# GD32C231 register map
File version: 1.0
CPU: CM23 r0p0, little endian, MPU, FPU, 4 interrupt priority bits
Registers are 32-bit, read-write, reset 0x0 unless marked. A register's access mark holds for its fields unless they carry their own. Offsets are from the block's base; [hi:lo] are bit positions; {n}, {i} and the like mark numbered series; 'fields as' and 'values as' point back to an identical list.

## CRC — Cyclic redundancy checks management unit
Base 0x40023000
0x00 DATA reset 0xFFFFFFFF
  [31:0] DATA — CRC calculation result bits
0x04 FDATA — Free data register
  [7:0] FDATA — Free data register bits
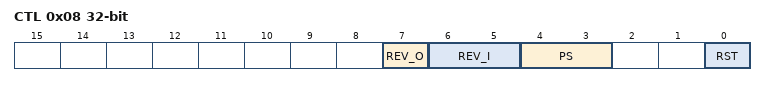
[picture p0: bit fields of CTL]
0x08 CTL — Control register
  [7] REV_O — Reverse output data value in bit order
  [6:5] REV_I — Reverse type for input data
  [4:3] PS — Size of polynomial
  [0] RST — Software writes and reads.
0x10 IDATA reset 0xFFFFFFFF — Initialization data register
  [31:0] IDATA — Configurable initial CRC data value
0x14 POLY reset 0x4C11DB7 — Polynomial register
  [31:0] POLY — User configurable polynomial value

## DBGMCU — Debug support
Base 0x40015800
0x00 ID ro — ID code register
  [31:0] ID_CODE — DBG ID code register
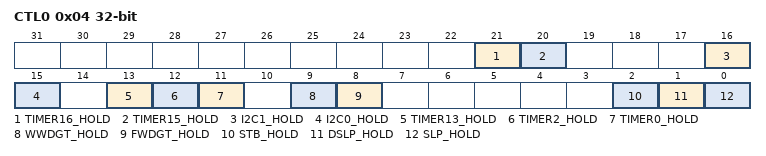
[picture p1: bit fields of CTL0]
0x04 CTL0 — Control register 0
  [21] TIMER16_HOLD — TIMER 16 hold bit
  [20] TIMER15_HOLD — TIMER 15 hold bit
  [16] I2C1_HOLD — I2C1 hold bit
  [15] I2C0_HOLD — I2C0 hold bit
  [13] TIMER13_HOLD — TIMER 13 hold bit
  [12] TIMER2_HOLD — TIMER 2 hold bit
  [11] TIMER0_HOLD — TIMER 0 hold bit
  [9] WWDGT_HOLD — WWDGT hold bit
  [8] FWDGT_HOLD — FWDGT hold bit
  [2] STB_HOLD — Standby mode hold bit
  [1] DSLP_HOLD — Deep-sleep mode hold bit
  [0] SLP_HOLD — Sleep mode hold bit
0x08 CTL1 — Control register 1
  [10] RTC_HOLD — RTC hold bit

## DMA — DMA controller
Base 0x40020000
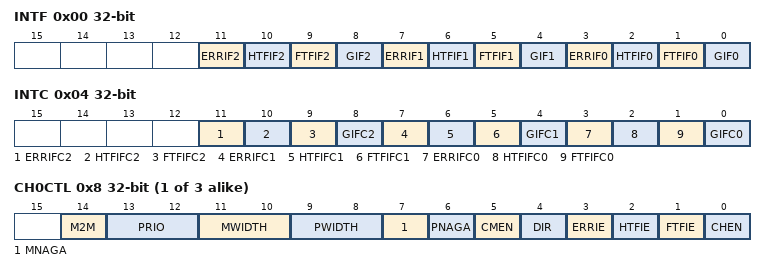
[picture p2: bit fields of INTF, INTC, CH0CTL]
0x00 INTF ro — DMA interrupt flag register (DMA_INTF)
  [11] ERRIF2 — Channel 2 Error flag
  [10] HTFIF2 — Channel 2 Half Transfer Finish flag
  [9] FTFIF2 — Channel 2 Full Transfer Finish flag
  [8] GIF2 — Channel 2 Global interrupt flag
  [7] ERRIF1 — Channel 1 Error flag
  [6] HTFIF1 — Channel 1 Half Transfer Finish flag
  [5] FTFIF1 — Channel 1 Full Transfer Finish flag
  [4] GIF1 — Channel 1 Global interrupt flag
  [3] ERRIF0 — Channel 0 Error flag
  [2] HTFIF0 — Channel 0 Half Transfer Finish flag
  [1] FTFIF0 — Channel 0 Full Transfer Finish flag
  [0] GIF0 — Channel 0 Global interrupt flag
0x04 INTC wo — DMA interrupt flag clear register (DMA_INTC)
  [11] ERRIFC2 — Channel 2 Error clear
  [10] HTFIFC2 — Channel 2 Half Transfer clear
  [9] FTFIFC2 — Channel 2 Full Transfer Finish clear
  [8] GIFC2 — Channel 2 Global interrupt flag clear
  [7] ERRIFC1 — Channel 1 Error clear
  [6] HTFIFC1 — Channel 1 Half Transfer clear
  [5] FTFIFC1 — Channel 1 Full Transfer Finish clear
  [4] GIFC1 — Channel 1 Global interrupt flag clear
  [3] ERRIFC0 — Channel 0 Error clear
  [2] HTFIFC0 — Channel 0 Half Transfer clear
  [1] FTFIFC0 — Channel 0 Full Transfer Finish clear
  [0] GIFC0 — Channel 0 Global interrupt flag clear
{0x8+0x14*i} CH{i}CTL (i=0..2) — DMA channel configuration register (DMA_CH{i}CTL)
  [14] M2M — Memory to memory mode
  [13:12] PRIO — Priority Level of this channel
  [11:10] MWIDTH — Transfer data size of memory
  [9:8] PWIDTH — Transfer data size of peripheral
  [7] MNAGA — Next address generation algorithm of memory
  [6] PNAGA — Next address generation algorithm of peripheral
  [5] CMEN — Circular mode enable
  [4] DIR — Transfer direction
  [3] ERRIE — Error interrupt enable
  [2] HTFIE — Half Transfer Finish interrupt enable
  [1] FTFIE — Full Transfer Finish interrupt enable
  [0] CHEN — Channel enable
{0xC+0x14*i} CH{i}CNT (i=0..2) — DMA channel {i} counter register
  [15:0] CNT — Transfer counter
{0x10+0x14*i} CH{i}PADDR (i=0..2) — DMA channel {i} peripheral base address register
  [31:0] PADDR — Peripheral base address
{0x14+0x14*i} CH{i}MADDR (i=0..2) — DMA channel {i} memory base address register
  [31:0] MADDR — Memory address

## DMAMUX — DMAMUX controller
Base 0x40020800
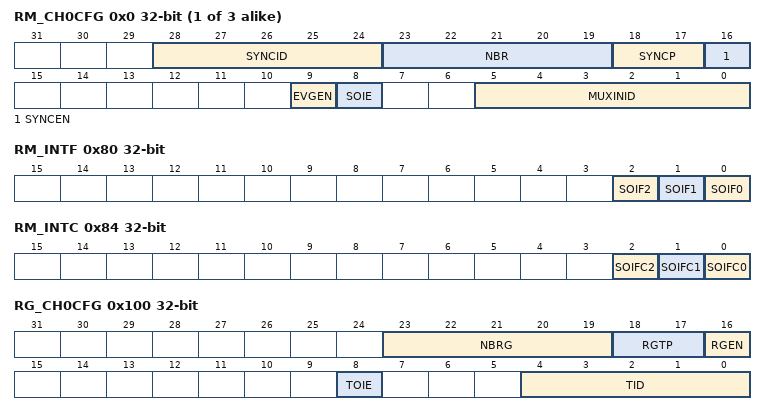
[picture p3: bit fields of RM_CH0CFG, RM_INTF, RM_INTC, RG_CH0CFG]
{0x0+4i} RM_CH{i}CFG (i=0..2) — Request multiplexer channel x configuration register
  [28:24] SYNCID — Synchronization input identification
  [23:19] NBR — Number of DMA requests to forward
  [18:17] SYNCP — Synchronization input polarity
  [16] SYNCEN — Synchronization enable
  [9] EVGEN — Event generation enable
  [8] SOIE — Synchronization overrun interrupt enable
  [5:0] MUXINID — Multiplexer input identification
0x80 RM_INTF ro — Request multiplexer channel interrupt flag register
  [2] SOIF2 — Synchronization overrun event flag of request multiplexer channel 2
  [1] SOIF1 — Synchronization overrun event flag of request multiplexer channel 1
  [0] SOIF0 — Synchronization overrun event flag of request multiplexer channel 0
0x84 RM_INTC wo — Request multiplexer channel interrupt flag clear register
  [2] SOIFC2 — Clear bit for synchronization overrun event flag of request multiplexer channel 2
  [1] SOIFC1 — Clear bit for synchronization overrun event flag of request multiplexer channel 1
  [0] SOIFC0 — Clear bit for synchronization overrun event flag of request multiplexer channel 0
0x100 RG_CH0CFG — Request generator channel x configuration register
  [23:19] NBRG — Number of DMA requests to be generated
  [18:17] RGTP — DMA request generator trigger polarity
  [16] RGEN — DMAMUX request generator channel x enable
  [8] TOIE — Trigger overrun interrupt enable
  [4:0] TID — Trigger input identification
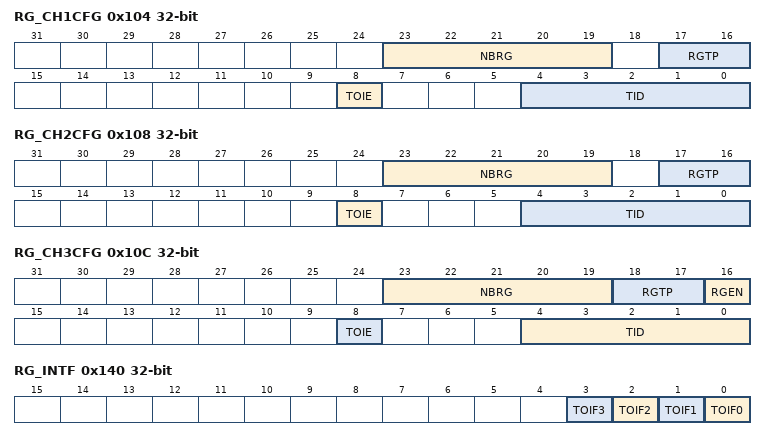
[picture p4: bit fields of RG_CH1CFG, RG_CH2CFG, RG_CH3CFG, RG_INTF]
0x104 RG_CH1CFG — Request generator channel 1 configuration register
  [23:19] NBRG — Number of DMA requests to be generated
  [17:16] RGTP — DMA request generator trigger polarity
  [8] TOIE — Trigger overrun interrupt enable
  [4:0] TID — Trigger input identification
0x108 RG_CH2CFG — Request generator channel 2 configuration register
  fields as RG_CH1CFG
0x10C RG_CH3CFG — Request generator channel x configuration register
  fields as RG_CH0CFG
0x140 RG_INTF ro — Request generator interrupt flag register
  [n] TOIF{n} (n=0..3) — Trigger overrun event flag of request generator channel {n}
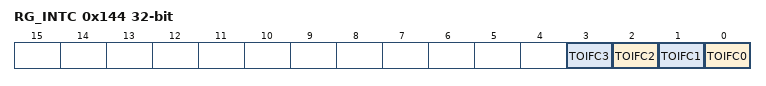
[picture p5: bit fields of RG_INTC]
0x144 RG_INTC ro — Rquest generator interrupt flag clear register
  [n] TOIFC{n} (n=0..3) — Clear bit for trigger overrun event flag of request generator channel {n}
